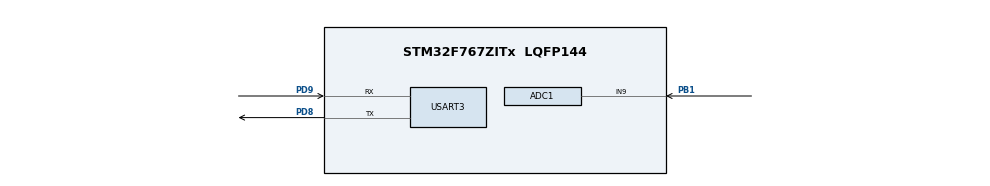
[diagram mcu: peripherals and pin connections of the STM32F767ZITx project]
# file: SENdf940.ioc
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ADC1.Channel-1\#ChannelRegularConversion=ADC_CHANNEL_9
ADC1.NbrOfConversionFlag=1
ADC1.Rank-1\#ChannelRegularConversion=1
ADC1.SamplingTime-1\#ChannelRegularConversion=ADC_SAMPLETIME_3CYCLES
ADC1.master=1
Mcu.Family=STM32F7
Mcu.Name=STM32F767ZITx
Mcu.Package=LQFP144
NVIC.PriorityGroup=NVIC_PRIORITYGROUP_4
PA13.Mode=Serial_Wire
PA13.Signal=SYS_JTMS-SWDIO
PA14.Mode=Serial_Wire
PA14.Signal=SYS_JTCK-SWCLK
PB1.Signal=ADCx_IN9
PC14/OSC32_IN.Mode=LSE-External-Oscillator
PC14/OSC32_IN.Signal=RCC_OSC32_IN
PC15/OSC32_OUT.Mode=LSE-External-Oscillator
PC15/OSC32_OUT.Signal=RCC_OSC32_OUT
PD8.Mode=Asynchronous
PD8.Signal=USART3_TX
PD9.Mode=Asynchronous
PD9.Signal=USART3_RX
PH0/OSC_IN.Mode=HSE-External-Oscillator
PH0/OSC_IN.Signal=RCC_OSC_IN
PH1/OSC_OUT.Mode=HSE-External-Oscillator
PH1/OSC_OUT.Signal=RCC_OSC_OUT
ProjectManager.HeapSize=0x200
ProjectManager.StackSize=0x400
ProjectManager.TargetToolchain=STM32CubeIDE
RCC.HSE_VALUE=25000000
RCC.HSI_VALUE=16000000
RCC.USBFreq_Value=96000000
RCC.VCOOutputFreq_Value=192000000
RTC.Date=23
RTC.Month=RTC_MONTH_OCTOBER
RTC.Year=23
SH.ADCx_IN9.0=ADC1_IN9,IN9
USART3.VirtualMode-Asynchronous=VM_ASYNC
VP_RTC_VS_RTC_Activate.Mode=RTC_Enabled
VP_RTC_VS_RTC_Calendar.Mode=RTC_Calendar
board=custom

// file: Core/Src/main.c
/* USER CODE BEGIN Header */
/**
  ******************************************************************************
  * @file           : main.c
  * @brief          : Main program body
  ******************************************************************************
  * @attention
  *
  * Copyright (c) 2023 STMicroelectronics.
  * All rights reserved.
  *
  * This software is licensed under terms that can be found in the LICENSE file
  * in the root directory of this software component.
  * If no LICENSE file comes with this software, it is provided AS-IS.
  *
  ******************************************************************************
  */
/* USER CODE END Header */
#include "main.h"

/* USER CODE BEGIN PTD */
char timestamp[22];
RTC_TimeTypeDef sTime;
RTC_DateTypeDef sDate;

/* USER CODE END PTD */

ADC_HandleTypeDef hadc1;

RTC_HandleTypeDef hrtc;

UART_HandleTypeDef huart3;

void SystemClock_Config(void);
static void MPU_Initialize(void);
static void MPU_Config(void);
static void MX_GPIO_Init(void);
static void MX_ADC1_Init(void);
static void MX_USART3_UART_Init(void);
static void MX_RTC_Init(void);

int main(void)
{
  /* USER CODE BEGIN 1 */
	uint32_t raw;
	char msg[10];

  /* USER CODE END 1 */

  /* MCU Configuration--------------------------------------------------------*/

  /* Reset of all peripherals, Initializes the Flash interface and the Systick. */
  HAL_Init();

  /* MPU Configuration--------------------------------------------------------*/
  MPU_Config();

  /* Configure the system clock */
  SystemClock_Config();

  /* Initialize all configured peripherals */
  MX_GPIO_Init();
  MX_ADC1_Init();
  MX_USART3_UART_Init();
  MX_RTC_Init();

  /* Infinite loop */
  /* USER CODE BEGIN WHILE */

  sTime.Hours = 0x01;
  sTime.Minutes = 0x30;
  sTime.Seconds = 0x0;

  if (HAL_RTC_SetTime(&hrtc, &sTime, RTC_FORMAT_BCD) != HAL_OK)
   {
 	  Error_Handler();
   }

  while (1)
  {

	    HAL_RTC_GetDate(&hrtc, &sDate, RTC_FORMAT_BIN);
	    HAL_RTC_GetTime(&hrtc, &sTime, RTC_FORMAT_BIN);
	    sprintf(timestamp, "%02d-%02d-%02d %02d.%02d.%02d\r\n",
	            sDate.Year, sDate.Month, sDate.Date,
	            sTime.Hours, sTime.Minutes, sTime.Seconds);
	    HAL_UART_Transmit(&huart3, (uint8_t *)&timestamp, strlen(timestamp), 1000);
	    HAL_Delay(2000);

	    HAL_ADC_Start(&hadc1);
	    HAL_ADC_PollForConversion(&hadc1, HAL_MAX_DELAY); //consulta
	    raw = HAL_ADC_GetValue(&hadc1); //guarda en memoria
	    sprintf(msg, "%lu\r\n", (unsigned long)raw); //crear la cadena
	    HAL_UART_Transmit(&huart3, (uint8_t *)msg, strlen(msg), HAL_MAX_DELAY);
	    HAL_Delay(1000);

    /* USER CODE END WHILE */

  }
}

void SystemClock_Config(void)
{
  RCC_OscInitTypeDef RCC_OscInitStruct = {0};
  RCC_ClkInitTypeDef RCC_ClkInitStruct = {0};

  /** Configure LSE Drive Capability
  */
  HAL_PWR_EnableBkUpAccess();

  /** Configure the main internal regulator output voltage
  */
  __HAL_RCC_PWR_CLK_ENABLE();
  __HAL_PWR_VOLTAGESCALING_CONFIG(PWR_REGULATOR_VOLTAGE_SCALE3);

  /** Initializes the RCC Oscillators according to the specified parameters
  * in the RCC_OscInitTypeDef structure.
  */
  RCC_OscInitStruct.OscillatorType = RCC_OSCILLATORTYPE_HSI|RCC_OSCILLATORTYPE_LSI;
  RCC_OscInitStruct.HSIState = RCC_HSI_ON;
  RCC_OscInitStruct.HSICalibrationValue = RCC_HSICALIBRATION_DEFAULT;
  RCC_OscInitStruct.LSIState = RCC_LSI_ON;
  RCC_OscInitStruct.PLL.PLLState = RCC_PLL_NONE;
  if (HAL_RCC_OscConfig(&RCC_OscInitStruct) != HAL_OK)
  {
    Error_Handler();
  }

  /** Initializes the CPU, AHB and APB buses clocks
  */
  RCC_ClkInitStruct.ClockType = RCC_CLOCKTYPE_HCLK|RCC_CLOCKTYPE_SYSCLK
                              |RCC_CLOCKTYPE_PCLK1|RCC_CLOCKTYPE_PCLK2;
  RCC_ClkInitStruct.SYSCLKSource = RCC_SYSCLKSOURCE_HSI;
  RCC_ClkInitStruct.AHBCLKDivider = RCC_SYSCLK_DIV1;
  RCC_ClkInitStruct.APB1CLKDivider = RCC_HCLK_DIV1;
  RCC_ClkInitStruct.APB2CLKDivider = RCC_HCLK_DIV1;

  if (HAL_RCC_ClockConfig(&RCC_ClkInitStruct, FLASH_LATENCY_0) != HAL_OK)
  {
    Error_Handler();
  }
}

static void MX_ADC1_Init(void)
{

  ADC_ChannelConfTypeDef sConfig = {0};

  /** Configure the global features of the ADC (Clock, Resolution, Data Alignment and number of conversion)
  */
  hadc1.Instance = ADC1;
  hadc1.Init.ClockPrescaler = ADC_CLOCK_SYNC_PCLK_DIV2;
  hadc1.Init.Resolution = ADC_RESOLUTION_12B;
  hadc1.Init.ScanConvMode = ADC_SCAN_DISABLE;
  hadc1.Init.ContinuousConvMode = DISABLE;
  hadc1.Init.DiscontinuousConvMode = DISABLE;
  hadc1.Init.ExternalTrigConvEdge = ADC_EXTERNALTRIGCONVEDGE_NONE;
  hadc1.Init.ExternalTrigConv = ADC_SOFTWARE_START;
  hadc1.Init.DataAlign = ADC_DATAALIGN_RIGHT;
  hadc1.Init.NbrOfConversion = 1;
  hadc1.Init.DMAContinuousRequests = DISABLE;
  hadc1.Init.EOCSelection = ADC_EOC_SINGLE_CONV;
  if (HAL_ADC_Init(&hadc1) != HAL_OK)
  {
    Error_Handler();
  }

  /** Configure for the selected ADC regular channel its corresponding rank in the sequencer and its sample time.
  */
  sConfig.Channel = ADC_CHANNEL_9;
  sConfig.Rank = ADC_REGULAR_RANK_1;
  sConfig.SamplingTime = ADC_SAMPLETIME_3CYCLES;
  if (HAL_ADC_ConfigChannel(&hadc1, &sConfig) != HAL_OK)
  {
    Error_Handler();
  }

}

static void MX_RTC_Init(void)
{

  RTC_TimeTypeDef sTime = {0};
  RTC_DateTypeDef sDate = {0};

  /** Initialize RTC Only
  */
  hrtc.Instance = RTC;
  hrtc.Init.HourFormat = RTC_HOURFORMAT_24;
  hrtc.Init.AsynchPrediv = 127;
  hrtc.Init.SynchPrediv = 255;
  hrtc.Init.OutPut = RTC_OUTPUT_DISABLE;
  hrtc.Init.OutPutPolarity = RTC_OUTPUT_POLARITY_HIGH;
  hrtc.Init.OutPutType = RTC_OUTPUT_TYPE_OPENDRAIN;
  if (HAL_RTC_Init(&hrtc) != HAL_OK)
  {
    Error_Handler();
  }

  /** Initialize RTC and set the Time and Date
  */
  sTime.Hours = 0x0;
  sTime.Minutes = 0x0;
  sTime.Seconds = 0x0;
  sTime.DayLightSaving = RTC_DAYLIGHTSAVING_NONE;
  sTime.StoreOperation = RTC_STOREOPERATION_RESET;
  if (HAL_RTC_SetTime(&hrtc, &sTime, RTC_FORMAT_BCD) != HAL_OK)
  {
    Error_Handler();
  }
  sDate.WeekDay = RTC_WEEKDAY_MONDAY;
  sDate.Month = RTC_MONTH_OCTOBER;
  sDate.Date = 0x23;
  sDate.Year = 0x23;

  if (HAL_RTC_SetDate(&hrtc, &sDate, RTC_FORMAT_BCD) != HAL_OK)
  {
    Error_Handler();
  }

}

static void MX_USART3_UART_Init(void)
{

  huart3.Instance = USART3;
  huart3.Init.BaudRate = 115200;
  huart3.Init.WordLength = UART_WORDLENGTH_8B;
  huart3.Init.StopBits = UART_STOPBITS_1;
  huart3.Init.Parity = UART_PARITY_NONE;
  huart3.Init.Mode = UART_MODE_TX_RX;
  huart3.Init.HwFlowCtl = UART_HWCONTROL_NONE;
  huart3.Init.OverSampling = UART_OVERSAMPLING_16;
  huart3.Init.OneBitSampling = UART_ONE_BIT_SAMPLE_DISABLE;
  huart3.AdvancedInit.AdvFeatureInit = UART_ADVFEATURE_NO_INIT;
  if (HAL_UART_Init(&huart3) != HAL_OK)
  {
    Error_Handler();
  }

}

static void MX_GPIO_Init(void)
{

  /* GPIO Ports Clock Enable */
  __HAL_RCC_GPIOC_CLK_ENABLE();
  __HAL_RCC_GPIOH_CLK_ENABLE();
  __HAL_RCC_GPIOB_CLK_ENABLE();
  __HAL_RCC_GPIOD_CLK_ENABLE();
  __HAL_RCC_GPIOA_CLK_ENABLE();

}

/* MPU Configuration */

void MPU_Config(void)
{
  MPU_Region_InitTypeDef MPU_InitStruct = {0};

  /* Disables the MPU */
  HAL_MPU_Disable();

  /** Initializes and configures the Region and the memory to be protected
  */
  MPU_InitStruct.Enable = MPU_REGION_ENABLE;
  MPU_InitStruct.Number = MPU_REGION_NUMBER0;
  MPU_InitStruct.BaseAddress = 0x0;
  MPU_InitStruct.Size = MPU_REGION_SIZE_4GB;
  MPU_InitStruct.SubRegionDisable = 0x87;
  MPU_InitStruct.TypeExtField = MPU_TEX_LEVEL0;
  MPU_InitStruct.AccessPermission = MPU_REGION_NO_ACCESS;
  MPU_InitStruct.DisableExec = MPU_INSTRUCTION_ACCESS_DISABLE;
  MPU_InitStruct.IsShareable = MPU_ACCESS_SHAREABLE;
  MPU_InitStruct.IsCacheable = MPU_ACCESS_NOT_CACHEABLE;
  MPU_InitStruct.IsBufferable = MPU_ACCESS_NOT_BUFFERABLE;

  HAL_MPU_ConfigRegion(&MPU_InitStruct);
  /* Enables the MPU */
  HAL_MPU_Enable(MPU_PRIVILEGED_DEFAULT);

}

void Error_Handler(void)
{
  __disable_irq();
  while (1)
  {
  }
}
